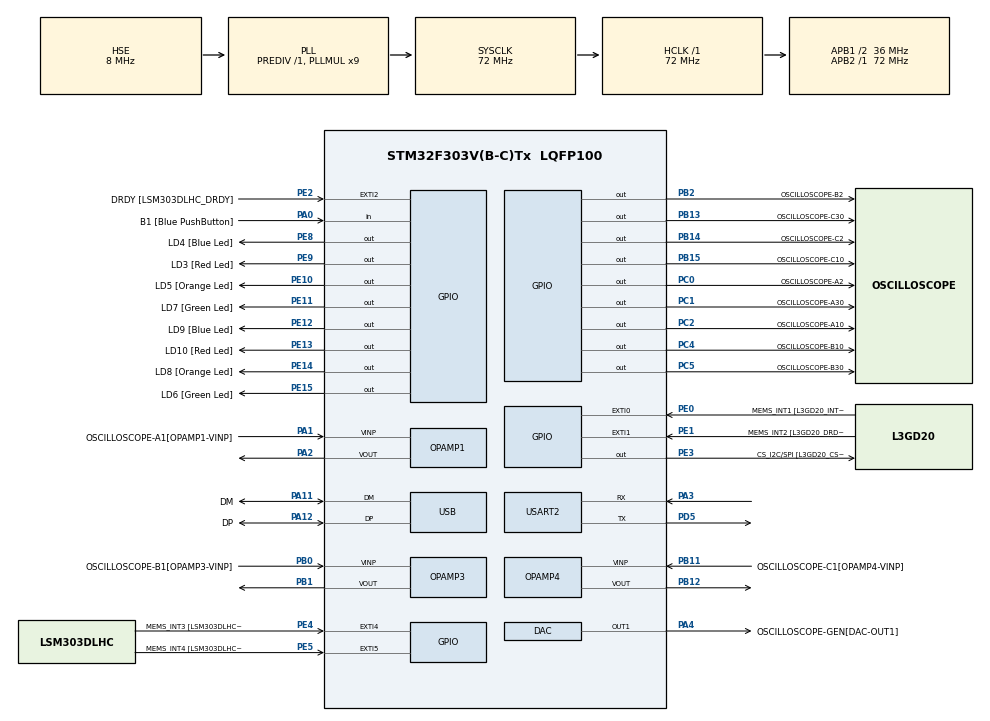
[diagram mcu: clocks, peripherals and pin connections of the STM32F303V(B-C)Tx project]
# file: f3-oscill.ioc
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ADC1.AWD1HighThreshold=4095
ADC1.AWD1ITMode=ENABLE
ADC1.AWD1LowThreshold=0
ADC1.Channel-0\#ChannelRegularConversion=ADC_CHANNEL_3
ADC1.ClockPrescaler=ADC_CLOCK_ASYNC
ADC1.ContinuousConvMode=DISABLE
ADC1.DMAContinuousRequests=ENABLE
ADC1.DataAlign=ADC_DATAALIGN_RIGHT
ADC1.DiscontinuousConvMode=DISABLE
ADC1.EOCSelection=EOC_SINGLE_CONV
ADC1.EnableAnalogWatchDog1=true
ADC1.EnableAnalogWatchDog2=false
ADC1.EnableAnalogWatchDog3=false
ADC1.EnableInjectedConversion=DISABLE
ADC1.EnableRegularConversion=ENABLE
ADC1.ExternalTrigConv=ADC_EXTERNALTRIGCONV_T1_TRGO
ADC1.ExternalTrigConvEdge=ADC_EXTERNALTRIGCONVEDGE_RISING
ADC1.LowPowerAutoWait=DISABLE
ADC1.NbrOfConversion=1
ADC1.NbrOfConversionFlag=1
ADC1.Offset-0\#ChannelRegularConversion=0
ADC1.OffsetNumber-0\#ChannelRegularConversion=ADC_OFFSET_NONE
ADC1.Overrun=OVR_DATA_OVERWRITTEN
ADC1.Rank-0\#ChannelRegularConversion=1
ADC1.Resolution=ADC_RESOLUTION12b
ADC1.SamplingTime-0\#ChannelRegularConversion=ADC_SAMPLETIME_1CYCLE_5
ADC1.ScanConvMode=ADC_SCAN_DISABLE
ADC1.WatchdogChannel=ADC_CHANNEL_3
ADC1.WatchdogMode=ADC_ANALOGWATCHDOG_SINGLE_REG
ADC1.master=1
ADC3.AWD1HighThreshold=4095
ADC3.AWD1ITMode=ENABLE
ADC3.Channel-0\#ChannelRegularConversion=ADC_CHANNEL_1
ADC3.ClockPrescaler=ADC_CLOCK_ASYNC
ADC3.DMAContinuousRequests=ENABLE
ADC3.EnableAnalogWatchDog1=true
ADC3.EnableInjectedConversion=DISABLE
ADC3.ExternalTrigConv=ADC_EXTERNALTRIGCONV_T1_TRGO
ADC3.ExternalTrigConvEdge=ADC_EXTERNALTRIGCONVEDGE_RISING
ADC3.NbrOfConversionFlag=1
ADC3.Offset-0\#ChannelRegularConversion=0
ADC3.OffsetNumber-0\#ChannelRegularConversion=ADC_OFFSET_NONE
ADC3.Rank-0\#ChannelRegularConversion=1
ADC3.SamplingTime-0\#ChannelRegularConversion=ADC_SAMPLETIME_1CYCLE_5
ADC3.master=1
ADC4.AWD1HighThreshold=4095
ADC4.AWD1ITMode=ENABLE
ADC4.Channel-0\#ChannelRegularConversion=ADC_CHANNEL_3
ADC4.DMAContinuousRequests=ENABLE
ADC4.EnableAnalogWatchDog1=true
ADC4.EnableInjectedConversion=DISABLE
ADC4.ExternalTrigConv=ADC_EXTERNALTRIGCONV_T1_TRGO
ADC4.ExternalTrigConvEdge=ADC_EXTERNALTRIGCONVEDGE_RISING
ADC4.NbrOfConversionFlag=1
ADC4.Offset-0\#ChannelRegularConversion=0
ADC4.OffsetNumber-0\#ChannelRegularConversion=ADC_OFFSET_NONE
ADC4.Rank-0\#ChannelRegularConversion=1
ADC4.SamplingTime-0\#ChannelRegularConversion=ADC_SAMPLETIME_1CYCLE_5
ADC4.WatchdogChannel=ADC_CHANNEL_3
DAC.DAC_Trigger=DAC_TRIGGER_T2_TRGO
DAC.WaveGeneration=DISABLE
Dma.ADC1.0.Direction=DMA_PERIPH_TO_MEMORY
Dma.ADC1.0.Instance=DMA1_Channel1
Dma.ADC1.0.MemDataAlignment=DMA_MDATAALIGN_HALFWORD
Dma.ADC1.0.MemInc=DMA_MINC_ENABLE
Dma.ADC1.0.Mode=DMA_CIRCULAR
Dma.ADC1.0.PeriphDataAlignment=DMA_PDATAALIGN_HALFWORD
Dma.ADC1.0.PeriphInc=DMA_PINC_DISABLE
Dma.ADC1.0.Priority=DMA_PRIORITY_LOW
Dma.ADC3.1.Direction=DMA_PERIPH_TO_MEMORY
Dma.ADC3.1.Instance=DMA2_Channel5
Dma.ADC3.1.MemDataAlignment=DMA_MDATAALIGN_HALFWORD
Dma.ADC3.1.MemInc=DMA_MINC_ENABLE
Dma.ADC3.1.Mode=DMA_CIRCULAR
Dma.ADC3.1.PeriphDataAlignment=DMA_PDATAALIGN_HALFWORD
Dma.ADC3.1.PeriphInc=DMA_PINC_DISABLE
Dma.ADC3.1.Priority=DMA_PRIORITY_LOW
Dma.ADC4.2.DMA_Remap=HAL_REMAPDMA_ADC24_DMA2_CH34
Dma.ADC4.2.Direction=DMA_PERIPH_TO_MEMORY
Dma.ADC4.2.Instance=DMA2_Channel4
Dma.ADC4.2.MemDataAlignment=DMA_MDATAALIGN_HALFWORD
Dma.ADC4.2.MemInc=DMA_MINC_ENABLE
Dma.ADC4.2.Mode=DMA_CIRCULAR
Dma.ADC4.2.PeriphDataAlignment=DMA_PDATAALIGN_HALFWORD
Dma.ADC4.2.PeriphInc=DMA_PINC_DISABLE
Dma.ADC4.2.Priority=DMA_PRIORITY_LOW
Dma.DAC_CH1.3.Direction=DMA_MEMORY_TO_PERIPH
Dma.DAC_CH1.3.Instance=DMA2_Channel3
Dma.DAC_CH1.3.MemDataAlignment=DMA_MDATAALIGN_HALFWORD
Dma.DAC_CH1.3.MemInc=DMA_MINC_ENABLE
Dma.DAC_CH1.3.Mode=DMA_CIRCULAR
Dma.DAC_CH1.3.PeriphDataAlignment=DMA_PDATAALIGN_HALFWORD
Dma.DAC_CH1.3.PeriphInc=DMA_PINC_DISABLE
Dma.DAC_CH1.3.Priority=DMA_PRIORITY_LOW
Dma.Request0=ADC1
Dma.Request1=ADC3
Dma.Request2=ADC4
Dma.Request3=DAC_CH1
Mcu.Family=STM32F3
Mcu.Name=STM32F303V(B-C)Tx
Mcu.Package=LQFP100
NVIC.ADC1_2_IRQn=true\:0\:0\:false
NVIC.ADC3_IRQn=true\:0\:0\:false
NVIC.ADC4_IRQn=true\:0\:0\:false
NVIC.DMA1_Channel1_IRQn=true\:0\:0\:false
NVIC.DMA2_Channel3_IRQn=true\:0\:0\:false
NVIC.DMA2_Channel4_IRQn=true\:0\:0\:false
NVIC.DMA2_Channel5_IRQn=true\:0\:0\:false
NVIC.PriorityGroup=NVIC_PRIORITYGROUP_0
NVIC.TIM3_IRQn=true\:0\:0\:false
NVIC.USB_LP_CAN_RX0_IRQn=true\:0\:0\:false
PA0.GPIO_Label=B1 [Blue PushButton]
PA0.GPIO_Mode=GPIO_MODE_INPUT
PA0.GPIO_PuPd=GPIO_NOPULL
PA0.Signal=GPIO_Input
PA1.GPIO_Label=OSCILLOSCOPE-A1[OPAMP1-VINP]
PA1.GPIO_Mode=GPIO_MODE_ANALOG
PA1.GPIO_PuPd=GPIO_NOPULL
PA1.Mode=PGA Not Connected
PA1.Signal=OPAMP1_VINP
PA11.GPIO_Label=DM
PA11.GPIO_Mode=GPIO_MODE_AF_PP
PA11.GPIO_PuPd=GPIO_NOPULL
PA11.GPIO_Speed=GPIO_SPEED_HIGH
PA11.Mode=Device
PA11.Signal=USB_DM
PA12.GPIO_Label=DP
PA12.GPIO_Mode=GPIO_MODE_AF_PP
PA12.GPIO_PuPd=GPIO_NOPULL
PA12.GPIO_Speed=GPIO_SPEED_HIGH
PA12.Mode=Device
PA12.Signal=USB_DP
PA13.GPIO_Label=SWDIO
PA13.Mode=Trace-Asynchronous_SW
PA13.Signal=SYS_JTMS-SWDIO
PA14.GPIO_Label=SWCLK
PA14.Mode=Trace-Asynchronous_SW
PA14.Signal=SYS_JTCK-SWCLK
PA2.Mode=PGA Not Connected
PA2.Signal=OPAMP1_VOUT
PA3.Mode=Asynchronous
PA3.Signal=USART2_RX
PA4.GPIO_Label=OSCILLOSCOPE-GEN[DAC-OUT1]
PA4.GPIO_Mode=GPIO_MODE_ANALOG
PA4.GPIO_PuPd=GPIO_NOPULL
PA4.Signal=COMP_DAC1_group
PA5.GPIO_Label=SPI1_SCK [L3GD20_SCL/SPC]
PA5.GPIO_Mode=GPIO_MODE_AF_PP
PA5.GPIO_PuPd=GPIO_NOPULL
PA5.GPIO_Speed=GPIO_SPEED_LOW
PA5.Signal=SPI1_SCK
PA6.GPIO_Label=SPI1_MISO [L3GD20_SA0/SDO]
PA6.GPIO_Mode=GPIO_MODE_AF_PP
PA6.GPIO_PuPd=GPIO_NOPULL
PA6.GPIO_Speed=GPIO_SPEED_LOW
PA6.Signal=SPI1_MISO
PA7.GPIO_Label=SPI1_MISO [L3GD20_SDA/SDI/SDO]
PA7.GPIO_Mode=GPIO_MODE_AF_PP
PA7.GPIO_PuPd=GPIO_NOPULL
PA7.GPIO_Speed=GPIO_SPEED_LOW
PA7.Signal=SPI1_MOSI
PB0.GPIO_Label=OSCILLOSCOPE-B1[OPAMP3-VINP]
PB0.GPIO_Mode=GPIO_MODE_ANALOG
PB0.GPIO_PuPd=GPIO_NOPULL
PB0.Mode=PGA Not Connected
PB0.Signal=OPAMP3_VINP
PB1.Mode=PGA Not Connected
PB1.Signal=OPAMP3_VOUT
PB11.GPIO_Label=OSCILLOSCOPE-C1[OPAMP4-VINP]
PB11.GPIO_Mode=GPIO_MODE_ANALOG
PB11.GPIO_PuPd=GPIO_NOPULL
PB11.Mode=PGA Not Connected
PB11.Signal=OPAMP4_VINP
PB12.Mode=PGA Not Connected
PB12.Signal=OPAMP4_VOUT
PB13.GPIO_Label=OSCILLOSCOPE-C30
PB13.GPIO_ModeDefaultOutputPP=GPIO_MODE_OUTPUT_OD
PB13.GPIO_PuPd=GPIO_NOPULL
PB13.GPIO_Speed=GPIO_SPEED_HIGH
PB13.Signal=GPIO_Output
PB14.GPIO_Label=OSCILLOSCOPE-C2
PB14.GPIO_ModeDefaultOutputPP=GPIO_MODE_OUTPUT_OD
PB14.GPIO_PuPd=GPIO_NOPULL
PB14.GPIO_Speed=GPIO_SPEED_HIGH
PB14.Signal=GPIO_Output
PB15.GPIO_Label=OSCILLOSCOPE-C10
PB15.GPIO_ModeDefaultOutputPP=GPIO_MODE_OUTPUT_OD
PB15.GPIO_PuPd=GPIO_NOPULL
PB15.GPIO_Speed=GPIO_SPEED_HIGH
PB15.Signal=GPIO_Output
PB2.GPIO_Label=OSCILLOSCOPE-B2
PB2.GPIO_ModeDefaultOutputPP=GPIO_MODE_OUTPUT_OD
PB2.GPIO_PuPd=GPIO_NOPULL
PB2.GPIO_Speed=GPIO_SPEED_HIGH
PB2.Signal=GPIO_Output
PB3.GPIO_Label=SWO
PB3.Mode=Trace-Asynchronous_SW
PB3.Signal=SYS_JTDO-TRACESWO
PB6.GPIO_FM6=__NULL
PB6.GPIO_Label=I2C1_SCL [LSM303DLHC_SCL]
PB6.GPIO_Mode=GPIO_MODE_AF_OD
PB6.GPIO_PuPd=GPIO_NOPULL
PB6.GPIO_PuPdOD=GPIO_PULLUP
PB6.GPIO_Speed=GPIO_SPEED_LOW
PB6.Signal=I2C1_SCL
PB7.GPIO_FM7=__NULL
PB7.GPIO_Label=I2C1_SDA [LSM303DLHC_SDA]
PB7.GPIO_Mode=GPIO_MODE_AF_OD
PB7.GPIO_PuPd=GPIO_NOPULL
PB7.GPIO_PuPdOD=GPIO_PULLUP
PB7.GPIO_Speed=GPIO_SPEED_LOW
PB7.Signal=I2C1_SDA
PC0.GPIO_Label=OSCILLOSCOPE-A2
PC0.GPIO_ModeDefaultOutputPP=GPIO_MODE_OUTPUT_OD
PC0.GPIO_PuPd=GPIO_NOPULL
PC0.GPIO_Speed=GPIO_SPEED_HIGH
PC0.Signal=GPIO_Output
PC1.GPIO_Label=OSCILLOSCOPE-A30
PC1.GPIO_ModeDefaultOutputPP=GPIO_MODE_OUTPUT_OD
PC1.GPIO_PuPd=GPIO_NOPULL
PC1.GPIO_Speed=GPIO_SPEED_HIGH
PC1.Signal=GPIO_Output
PC14-OSC32_IN.GPIO_Label=OSC32_IN
PC14-OSC32_IN.Signal=RCC_OSC32_IN
PC15-OSC32_OUT.GPIO_Label=OSC32_OUT
PC15-OSC32_OUT.Signal=RCC_OSC32_OUT
PC2.GPIO_Label=OSCILLOSCOPE-A10
PC2.GPIO_ModeDefaultOutputPP=GPIO_MODE_OUTPUT_OD
PC2.GPIO_PuPd=GPIO_NOPULL
PC2.GPIO_Speed=GPIO_SPEED_HIGH
PC2.Signal=GPIO_Output
PC4.GPIO_Label=OSCILLOSCOPE-B10
PC4.GPIO_ModeDefaultOutputPP=GPIO_MODE_OUTPUT_OD
PC4.GPIO_PuPd=GPIO_NOPULL
PC4.GPIO_Speed=GPIO_SPEED_HIGH
PC4.Signal=GPIO_Output
PC5.GPIO_Label=OSCILLOSCOPE-B30
PC5.GPIO_ModeDefaultOutputPP=GPIO_MODE_OUTPUT_OD
PC5.GPIO_PuPd=GPIO_NOPULL
PC5.GPIO_Speed=GPIO_SPEED_HIGH
PC5.Signal=GPIO_Output
PD5.Mode=Asynchronous
PD5.Signal=USART2_TX
PE0.GPIO_Label=MEMS_INT1 [L3GD20_INT1]
PE0.GPIO_ModeDefaultEXTI=GPIO_MODE_EVT_RISING
PE0.GPIO_PuPd=GPIO_NOPULL
PE0.Signal=GPXTI0
PE1.GPIO_Label=MEMS_INT2 [L3GD20_DRDY/INT2]
PE1.GPIO_ModeDefaultEXTI=GPIO_MODE_EVT_RISING
PE1.GPIO_PuPd=GPIO_NOPULL
PE1.Signal=GPXTI1
PE10.GPIO_Label=LD5 [Orange Led]
PE10.GPIO_ModeDefaultOutputPP=GPIO_MODE_OUTPUT_PP
PE10.GPIO_PuPd=GPIO_NOPULL
PE10.GPIO_Speed=GPIO_SPEED_LOW
PE10.Signal=GPIO_Output
PE11.GPIO_Label=LD7 [Green Led]
PE11.GPIO_ModeDefaultOutputPP=GPIO_MODE_OUTPUT_PP
PE11.GPIO_PuPd=GPIO_NOPULL
PE11.GPIO_Speed=GPIO_SPEED_LOW
PE11.Signal=GPIO_Output
PE12.GPIO_Label=LD9 [Blue Led]
PE12.GPIO_ModeDefaultOutputPP=GPIO_MODE_OUTPUT_PP
PE12.GPIO_PuPd=GPIO_NOPULL
PE12.GPIO_Speed=GPIO_SPEED_LOW
PE12.Signal=GPIO_Output
PE13.GPIO_Label=LD10 [Red Led]
PE13.GPIO_ModeDefaultOutputPP=GPIO_MODE_OUTPUT_PP
PE13.GPIO_PuPd=GPIO_NOPULL
PE13.GPIO_Speed=GPIO_SPEED_LOW
PE13.Signal=GPIO_Output
PE14.GPIO_Label=LD8 [Orange Led]
PE14.GPIO_ModeDefaultOutputPP=GPIO_MODE_OUTPUT_PP
PE14.GPIO_PuPd=GPIO_NOPULL
PE14.GPIO_Speed=GPIO_SPEED_LOW
PE14.Signal=GPIO_Output
PE15.GPIO_Label=LD6 [Green Led]
PE15.GPIO_ModeDefaultOutputPP=GPIO_MODE_OUTPUT_PP
PE15.GPIO_PuPd=GPIO_NOPULL
PE15.GPIO_Speed=GPIO_SPEED_LOW
PE15.Signal=GPIO_Output
PE2.GPIO_Label=DRDY [LSM303DLHC_DRDY]
PE2.GPIO_ModeDefaultEXTI=GPIO_MODE_EVT_RISING
PE2.GPIO_PuPd=GPIO_NOPULL
PE2.Signal=GPXTI2
PE3.GPIO_Label=CS_I2C/SPI [L3GD20_CS_I2C/SPI]
PE3.GPIO_ModeDefaultOutputPP=GPIO_MODE_OUTPUT_PP
PE3.GPIO_PuPd=GPIO_NOPULL
PE3.GPIO_Speed=GPIO_SPEED_LOW
PE3.Signal=GPIO_Output
PE4.GPIO_Label=MEMS_INT3 [LSM303DLHC_INT1]
PE4.GPIO_ModeDefaultEXTI=GPIO_MODE_EVT_RISING
PE4.GPIO_PuPd=GPIO_NOPULL
PE4.Signal=GPXTI4
PE5.GPIO_Label=MEMS_INT4 [LSM303DLHC_INT2]
PE5.GPIO_ModeDefaultEXTI=GPIO_MODE_EVT_RISING
PE5.GPIO_PuPd=GPIO_NOPULL
PE5.Signal=GPXTI5
PE7.GPIO_Label=OSCILLOSCOPE-EXT_SYNC[COMP4_INP]
PE7.GPIO_Mode=GPIO_MODE_ANALOG
PE7.GPIO_PuPd=GPIO_NOPULL
PE7.Signal=COMP4_INP
PE8.GPIO_Label=LD4 [Blue Led]
PE8.GPIO_ModeDefaultOutputPP=GPIO_MODE_OUTPUT_PP
PE8.GPIO_PuPd=GPIO_NOPULL
PE8.GPIO_Speed=GPIO_SPEED_LOW
PE8.Signal=GPIO_Output
PE9.GPIO_Label=LD3 [Red Led]
PE9.GPIO_ModeDefaultOutputPP=GPIO_MODE_OUTPUT_PP
PE9.GPIO_PuPd=GPIO_NOPULL
PE9.GPIO_Speed=GPIO_SPEED_LOW
PE9.Signal=GPIO_Output
PF0-OSC_IN.GPIO_Label=OSC_IN
PF0-OSC_IN.Mode=HSE-External-Clock-Source
PF0-OSC_IN.Signal=RCC_OSC_IN
PF1-OSC_OUT.GPIO_Label=OSC_OUT
PF1-OSC_OUT.Signal=RCC_OSC_OUT
ProjectManager.TargetToolchain=MDK-ARM V5
RCC.AHBFreq_Value=72000000
RCC.APB1CLKDivider=RCC_HCLK_DIV2
RCC.APB1Freq_Value=36000000
RCC.APB1TimFreq_Value=72000000
RCC.APB2Freq_Value=72000000
RCC.APB2TimFreq_Value=72000000
RCC.CortexFreq_Value=9000000
RCC.Cortex_Div=SYSTICK_CLKSOURCE_HCLK_DIV8
RCC.HCLKFreq_Value=72000000
RCC.HSE_VALUE=8000000
RCC.HSIState=RCC_HSI_ON
RCC.HSI_VALUE=8000000
RCC.LSE_VALUE=32768
RCC.PLLMUL=RCC_PLL_MUL9
RCC.PRESCALERUSB=RCC_USBPLLCLK_DIV1_5
RCC.SYSCLKFreq_VALUE=72000000
RCC.SYSCLKSourceVirtual=RCC_SYSCLKSOURCE_PLLCLK
RCC.USBFreq_Value=48000000
SH.COMP_DAC1_group.0=DAC_OUT1,DAC_OUT1
TIM1.Period=3000
TIM1.TIM_MasterOutputTrigger=TIM_TRGO_UPDATE
TIM2.Period=2000
TIM2.TIM_MasterOutputTrigger=TIM_TRGO_UPDATE
TIM3.Period=2095
VP_ADC1_OPAMP_OUT1.Mode=IN-OPAMP1-Single-Ended
VP_ADC3_OPAMP_OUT3.Mode=IN-OPAMP3-Single-Ended
VP_ADC4_OPAMP_OUT4.Mode=IN-OPAMP4-Single-Ended
VP_TIM1_VS_ClockSourceINT.Mode=Internal
VP_TIM2_VS_ClockSourceINT.Mode=Internal
VP_TIM3_VS_ClockSourceITR.Mode=TriggerSource_ITR0
VP_TIM3_VS_ControllerModeClock.Mode=Clock Mode
board=STM32F3DISCOVERY

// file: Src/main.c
/**
  ******************************************************************************
  * File Name          : main.c
  * Description        : Main program body
  ******************************************************************************
  *
  * COPYRIGHT(c) 2016 STMicroelectronics
  *
  * Redistribution and use in source and binary forms, with or without modification,
  * are permitted provided that the following conditions are met:
  *   1. Redistributions of source code must retain the above copyright notice,
  *      this list of conditions and the following disclaimer.
  *   2. Redistributions in binary form must reproduce the above copyright notice,
  *      this list of conditions and the following disclaimer in the documentation
  *      and/or other materials provided with the distribution.
  *   3. Neither the name of STMicroelectronics nor the names of its contributors
  *      may be used to endorse or promote products derived from this software
  *      without specific prior written permission.
  *
  * THIS SOFTWARE IS PROVIDED BY THE COPYRIGHT HOLDERS AND CONTRIBUTORS "AS IS"
  * AND ANY EXPRESS OR IMPLIED WARRANTIES, INCLUDING, BUT NOT LIMITED TO, THE
  * IMPLIED WARRANTIES OF MERCHANTABILITY AND FITNESS FOR A PARTICULAR PURPOSE ARE
  * DISCLAIMED. IN NO EVENT SHALL THE COPYRIGHT HOLDER OR CONTRIBUTORS BE LIABLE
  * FOR ANY DIRECT, INDIRECT, INCIDENTAL, SPECIAL, EXEMPLARY, OR CONSEQUENTIAL
  * DAMAGES (INCLUDING, BUT NOT LIMITED TO, PROCUREMENT OF SUBSTITUTE GOODS OR
  * SERVICES; LOSS OF USE, DATA, OR PROFITS; OR BUSINESS INTERRUPTION) HOWEVER
  * CAUSED AND ON ANY THEORY OF LIABILITY, WHETHER IN CONTRACT, STRICT LIABILITY,
  * OR TORT (INCLUDING NEGLIGENCE OR OTHERWISE) ARISING IN ANY WAY OUT OF THE USE
  * OF THIS SOFTWARE, EVEN IF ADVISED OF THE POSSIBILITY OF SUCH DAMAGE.
  *
  ******************************************************************************
  */
#include "stm32f3xx_hal.h"

/* USER CODE BEGIN Includes */
#include "usb_device.h"
#include "usbd_oscill_if.h"
#include "oscill.h"

/* USER CODE END Includes */

ADC_HandleTypeDef hadc1;
ADC_HandleTypeDef hadc3;
ADC_HandleTypeDef hadc4;
DMA_HandleTypeDef hdma_adc1;
DMA_HandleTypeDef hdma_adc3;
DMA_HandleTypeDef hdma_adc4;

DAC_HandleTypeDef hdac;
DMA_HandleTypeDef hdma_dac_ch1;

OPAMP_HandleTypeDef hopamp1;
OPAMP_HandleTypeDef hopamp3;
OPAMP_HandleTypeDef hopamp4;

TIM_HandleTypeDef htim1;
TIM_HandleTypeDef htim2;
TIM_HandleTypeDef htim3;

UART_HandleTypeDef huart2;

PCD_HandleTypeDef hpcd_USB_FS;

/* USER CODE BEGIN PV */
/* Private variables ---------------------------------------------------------*/
/* USER CODE END PV */

void SystemClock_Config(void);
static void MX_GPIO_Init(void);
static void MX_DMA_Init(void);
static void MX_ADC1_Init(void);
static void MX_ADC3_Init(void);
static void MX_ADC4_Init(void);
static void MX_DAC_Init(void);
static void MX_OPAMP1_Init(void);
static void MX_OPAMP3_Init(void);
static void MX_OPAMP4_Init(void);
static void MX_TIM1_Init(void);
static void MX_TIM2_Init(void);
static void MX_TIM3_Init(void);
static void MX_USART2_UART_Init(void);
static void MX_USB_PCD_Init(void);

/* USER CODE BEGIN PFP */
/* Private function prototypes -----------------------------------------------*/

/* USER CODE END PFP */

int main(void)
{

  /* USER CODE BEGIN 1 */
 	MX_USB_DEVICE_Init();

  /* USER CODE END 1 */

  /* MCU Configuration----------------------------------------------------------*/

  /* Reset of all peripherals, Initializes the Flash interface and the Systick. */
  HAL_Init();

  /* Configure the system clock */
  SystemClock_Config();

  /* Initialize all configured peripherals */
  MX_GPIO_Init();
  MX_DMA_Init();
  MX_ADC1_Init();
  MX_ADC3_Init();
  MX_ADC4_Init();
  MX_DAC_Init();
  MX_OPAMP1_Init();
  MX_OPAMP3_Init();
  MX_OPAMP4_Init();
  MX_TIM1_Init();
  MX_TIM2_Init();
  MX_TIM3_Init();
  MX_USART2_UART_Init();
  MX_USB_PCD_Init();

  /* USER CODE BEGIN 2 */
	initOscill();
  /* USER CODE END 2 */

  /* Infinite loop */
  while (1)
  {

  }

}

/** System Clock Configuration
*/
void SystemClock_Config(void)
{

  RCC_OscInitTypeDef RCC_OscInitStruct;
  RCC_ClkInitTypeDef RCC_ClkInitStruct;
  RCC_PeriphCLKInitTypeDef PeriphClkInit;

  RCC_OscInitStruct.OscillatorType = RCC_OSCILLATORTYPE_HSE;
  RCC_OscInitStruct.HSEState = RCC_HSE_BYPASS;
  RCC_OscInitStruct.HSEPredivValue = RCC_HSE_PREDIV_DIV1;
  RCC_OscInitStruct.PLL.PLLState = RCC_PLL_ON;
  RCC_OscInitStruct.PLL.PLLSource = RCC_PLLSOURCE_HSE;
  RCC_OscInitStruct.PLL.PLLMUL = RCC_PLL_MUL9;
  HAL_RCC_OscConfig(&RCC_OscInitStruct);

  RCC_ClkInitStruct.ClockType = RCC_CLOCKTYPE_SYSCLK|RCC_CLOCKTYPE_PCLK1;
  RCC_ClkInitStruct.SYSCLKSource = RCC_SYSCLKSOURCE_PLLCLK;
  RCC_ClkInitStruct.AHBCLKDivider = RCC_SYSCLK_DIV1;
  RCC_ClkInitStruct.APB1CLKDivider = RCC_HCLK_DIV2;
  RCC_ClkInitStruct.APB2CLKDivider = RCC_HCLK_DIV1;
  HAL_RCC_ClockConfig(&RCC_ClkInitStruct, FLASH_LATENCY_2);

  PeriphClkInit.PeriphClockSelection = RCC_PERIPHCLK_USB|RCC_PERIPHCLK_USART2
                              |RCC_PERIPHCLK_TIM1|RCC_PERIPHCLK_ADC12
                              |RCC_PERIPHCLK_ADC34;
  PeriphClkInit.Usart2ClockSelection = RCC_USART2CLKSOURCE_PCLK1;
  PeriphClkInit.Adc12ClockSelection = RCC_ADC12PLLCLK_DIV1;
  PeriphClkInit.Adc34ClockSelection = RCC_ADC34PLLCLK_DIV1;
  PeriphClkInit.USBClockSelection = RCC_USBPLLCLK_DIV1_5;
  PeriphClkInit.Tim1ClockSelection = RCC_TIM1CLK_HCLK;
  HAL_RCCEx_PeriphCLKConfig(&PeriphClkInit);

  HAL_SYSTICK_Config(HAL_RCC_GetHCLKFreq()/8000);

  HAL_SYSTICK_CLKSourceConfig(SYSTICK_CLKSOURCE_HCLK_DIV8);

  /* SysTick_IRQn interrupt configuration */
  HAL_NVIC_SetPriority(SysTick_IRQn, 0, 0);
}

/* ADC1 init function */
void MX_ADC1_Init(void)
{

  ADC_AnalogWDGConfTypeDef AnalogWDGConfig;
  ADC_ChannelConfTypeDef sConfig;

    /**Common config
    */
  hadc1.Instance = ADC1;
  hadc1.Init.ClockPrescaler = ADC_CLOCK_ASYNC;
  hadc1.Init.Resolution = ADC_RESOLUTION12b;
  hadc1.Init.ScanConvMode = ADC_SCAN_DISABLE;
  hadc1.Init.ContinuousConvMode = DISABLE;
  hadc1.Init.DiscontinuousConvMode = DISABLE;
  hadc1.Init.ExternalTrigConvEdge = ADC_EXTERNALTRIGCONVEDGE_RISING;
  hadc1.Init.ExternalTrigConv = ADC_EXTERNALTRIGCONV_T1_TRGO;
  hadc1.Init.DataAlign = ADC_DATAALIGN_RIGHT;
  hadc1.Init.NbrOfConversion = 1;
  hadc1.Init.DMAContinuousRequests = ENABLE;
  hadc1.Init.EOCSelection = EOC_SINGLE_CONV;
  hadc1.Init.LowPowerAutoWait = DISABLE;
  hadc1.Init.Overrun = OVR_DATA_OVERWRITTEN;
  HAL_ADC_Init(&hadc1);

    /**Configure Analog WatchDog 1
    */
  AnalogWDGConfig.WatchdogNumber = ADC_ANALOGWATCHDOG_1;
  AnalogWDGConfig.WatchdogMode = ADC_ANALOGWATCHDOG_SINGLE_REG;
  AnalogWDGConfig.HighThreshold = 4095;
  AnalogWDGConfig.LowThreshold = 0;
  AnalogWDGConfig.Channel = ADC_CHANNEL_3;
  AnalogWDGConfig.ITMode = ENABLE;
  HAL_ADC_AnalogWDGConfig(&hadc1, &AnalogWDGConfig);

    /**Configure Regular Channel
    */
  sConfig.Channel = ADC_CHANNEL_3;
  sConfig.Rank = 1;
  sConfig.SingleDiff = ADC_SINGLE_ENDED;
  sConfig.SamplingTime = ADC_SAMPLETIME_1CYCLE_5;
  sConfig.OffsetNumber = ADC_OFFSET_NONE;
  sConfig.Offset = 0;
  HAL_ADC_ConfigChannel(&hadc1, &sConfig);

}

/* ADC3 init function */
void MX_ADC3_Init(void)
{

  ADC_AnalogWDGConfTypeDef AnalogWDGConfig;
  ADC_ChannelConfTypeDef sConfig;

    /**Common config
    */
  hadc3.Instance = ADC3;
  hadc3.Init.ClockPrescaler = ADC_CLOCK_ASYNC;
  hadc3.Init.Resolution = ADC_RESOLUTION12b;
  hadc3.Init.ScanConvMode = ADC_SCAN_DISABLE;
  hadc3.Init.ContinuousConvMode = DISABLE;
  hadc3.Init.DiscontinuousConvMode = DISABLE;
  hadc3.Init.ExternalTrigConvEdge = ADC_EXTERNALTRIGCONVEDGE_RISING;
  hadc3.Init.ExternalTrigConv = ADC_EXTERNALTRIGCONV_T1_TRGO;
  hadc3.Init.DataAlign = ADC_DATAALIGN_RIGHT;
  hadc3.Init.NbrOfConversion = 1;
  hadc3.Init.DMAContinuousRequests = ENABLE;
  hadc3.Init.EOCSelection = EOC_SINGLE_CONV;
  hadc3.Init.LowPowerAutoWait = DISABLE;
  hadc3.Init.Overrun = OVR_DATA_OVERWRITTEN;
  HAL_ADC_Init(&hadc3);

    /**Configure Analog WatchDog 1
    */
  AnalogWDGConfig.WatchdogNumber = ADC_ANALOGWATCHDOG_1;
  AnalogWDGConfig.WatchdogMode = ADC_ANALOGWATCHDOG_SINGLE_REG;
  AnalogWDGConfig.HighThreshold = 4095;
  AnalogWDGConfig.LowThreshold = 0;
  AnalogWDGConfig.Channel = ADC_CHANNEL_1;
  AnalogWDGConfig.ITMode = ENABLE;
  HAL_ADC_AnalogWDGConfig(&hadc3, &AnalogWDGConfig);

    /**Configure Regular Channel
    */
  sConfig.Channel = ADC_CHANNEL_1;
  sConfig.Rank = 1;
  sConfig.SingleDiff = ADC_SINGLE_ENDED;
  sConfig.SamplingTime = ADC_SAMPLETIME_1CYCLE_5;
  sConfig.OffsetNumber = ADC_OFFSET_NONE;
  sConfig.Offset = 0;
  HAL_ADC_ConfigChannel(&hadc3, &sConfig);

}

/* ADC4 init function */
void MX_ADC4_Init(void)
{

  ADC_AnalogWDGConfTypeDef AnalogWDGConfig;
  ADC_ChannelConfTypeDef sConfig;

    /**Common config
    */
  hadc4.Instance = ADC4;
  hadc4.Init.ClockPrescaler = ADC_CLOCK_ASYNC;
  hadc4.Init.Resolution = ADC_RESOLUTION12b;
  hadc4.Init.ScanConvMode = ADC_SCAN_DISABLE;
  hadc4.Init.ContinuousConvMode = DISABLE;
  hadc4.Init.DiscontinuousConvMode = DISABLE;
  hadc4.Init.ExternalTrigConvEdge = ADC_EXTERNALTRIGCONVEDGE_RISING;
  hadc4.Init.ExternalTrigConv = ADC_EXTERNALTRIGCONV_T1_TRGO;
  hadc4.Init.DataAlign = ADC_DATAALIGN_RIGHT;
  hadc4.Init.NbrOfConversion = 1;
  hadc4.Init.DMAContinuousRequests = ENABLE;
  hadc4.Init.EOCSelection = EOC_SINGLE_CONV;
  hadc4.Init.LowPowerAutoWait = DISABLE;
  hadc4.Init.Overrun = OVR_DATA_OVERWRITTEN;
  HAL_ADC_Init(&hadc4);

    /**Configure Analog WatchDog 1
    */
  AnalogWDGConfig.WatchdogNumber = ADC_ANALOGWATCHDOG_1;
  AnalogWDGConfig.WatchdogMode = ADC_ANALOGWATCHDOG_SINGLE_REG;
  AnalogWDGConfig.HighThreshold = 4095;
  AnalogWDGConfig.LowThreshold = 0;
  AnalogWDGConfig.Channel = ADC_CHANNEL_3;
  AnalogWDGConfig.ITMode = ENABLE;
  HAL_ADC_AnalogWDGConfig(&hadc4, &AnalogWDGConfig);

    /**Configure Regular Channel
    */
  sConfig.Channel = ADC_CHANNEL_3;
  sConfig.Rank = 1;
  sConfig.SingleDiff = ADC_SINGLE_ENDED;
  sConfig.SamplingTime = ADC_SAMPLETIME_1CYCLE_5;
  sConfig.OffsetNumber = ADC_OFFSET_NONE;
  sConfig.Offset = 0;
  HAL_ADC_ConfigChannel(&hadc4, &sConfig);

}

/* DAC init function */
void MX_DAC_Init(void)
{

  DAC_ChannelConfTypeDef sConfig;

    /**DAC Initialization
    */
  hdac.Instance = DAC;
  HAL_DAC_Init(&hdac);

    /**DAC channel OUT1 config
    */
  sConfig.DAC_Trigger = DAC_TRIGGER_T2_TRGO;
  sConfig.DAC_OutputBuffer = DAC_OUTPUTBUFFER_ENABLE;
  HAL_DAC_ConfigChannel(&hdac, &sConfig, DAC_CHANNEL_1);

}

/* OPAMP1 init function */
void MX_OPAMP1_Init(void)
{

  hopamp1.Instance = OPAMP1;
  hopamp1.Init.Mode = OPAMP_PGA_MODE;
  hopamp1.Init.NonInvertingInput = OPAMP_NONINVERTINGINPUT_VP0;
  hopamp1.Init.TimerControlledMuxmode = OPAMP_TIMERCONTROLLEDMUXMODE_DISABLE;
  hopamp1.Init.PgaConnect = OPAMP_PGACONNECT_NO;
  hopamp1.Init.PgaGain = OPAMP_PGA_GAIN_2;
  hopamp1.Init.UserTrimming = OPAMP_TRIMMING_FACTORY;
  HAL_OPAMP_Init(&hopamp1);

}

/* OPAMP3 init function */
void MX_OPAMP3_Init(void)
{

  hopamp3.Instance = OPAMP3;
  hopamp3.Init.Mode = OPAMP_PGA_MODE;
  hopamp3.Init.NonInvertingInput = OPAMP_NONINVERTINGINPUT_VP0;
  hopamp3.Init.TimerControlledMuxmode = OPAMP_TIMERCONTROLLEDMUXMODE_DISABLE;
  hopamp3.Init.PgaConnect = OPAMP_PGACONNECT_NO;
  hopamp3.Init.PgaGain = OPAMP_PGA_GAIN_2;
  hopamp3.Init.UserTrimming = OPAMP_TRIMMING_FACTORY;
  HAL_OPAMP_Init(&hopamp3);

}

/* OPAMP4 init function */
void MX_OPAMP4_Init(void)
{

  hopamp4.Instance = OPAMP4;
  hopamp4.Init.Mode = OPAMP_PGA_MODE;
  hopamp4.Init.NonInvertingInput = OPAMP_NONINVERTINGINPUT_VP2;
  hopamp4.Init.TimerControlledMuxmode = OPAMP_TIMERCONTROLLEDMUXMODE_DISABLE;
  hopamp4.Init.PgaConnect = OPAMP_PGACONNECT_NO;
  hopamp4.Init.PgaGain = OPAMP_PGA_GAIN_2;
  hopamp4.Init.UserTrimming = OPAMP_TRIMMING_FACTORY;
  HAL_OPAMP_Init(&hopamp4);

}

/* TIM1 init function */
void MX_TIM1_Init(void)
{

  TIM_ClockConfigTypeDef sClockSourceConfig;
  TIM_MasterConfigTypeDef sMasterConfig;

  htim1.Instance = TIM1;
  htim1.Init.Prescaler = 0;
  htim1.Init.CounterMode = TIM_COUNTERMODE_UP;
  htim1.Init.Period = 3000;
  htim1.Init.ClockDivision = TIM_CLOCKDIVISION_DIV1;
  htim1.Init.RepetitionCounter = 0;
  HAL_TIM_Base_Init(&htim1);

  sClockSourceConfig.ClockSource = TIM_CLOCKSOURCE_INTERNAL;
  HAL_TIM_ConfigClockSource(&htim1, &sClockSourceConfig);

  sMasterConfig.MasterOutputTrigger = TIM_TRGO_UPDATE;
  sMasterConfig.MasterOutputTrigger2 = TIM_TRGO2_RESET;
  sMasterConfig.MasterSlaveMode = TIM_MASTERSLAVEMODE_DISABLE;
  HAL_TIMEx_MasterConfigSynchronization(&htim1, &sMasterConfig);

}

/* TIM2 init function */
void MX_TIM2_Init(void)
{

  TIM_ClockConfigTypeDef sClockSourceConfig;
  TIM_MasterConfigTypeDef sMasterConfig;

  htim2.Instance = TIM2;
  htim2.Init.Prescaler = 0;
  htim2.Init.CounterMode = TIM_COUNTERMODE_UP;
  htim2.Init.Period = 2000;
  htim2.Init.ClockDivision = TIM_CLOCKDIVISION_DIV1;
  HAL_TIM_Base_Init(&htim2);

  sClockSourceConfig.ClockSource = TIM_CLOCKSOURCE_INTERNAL;
  HAL_TIM_ConfigClockSource(&htim2, &sClockSourceConfig);

  sMasterConfig.MasterOutputTrigger = TIM_TRGO_UPDATE;
  sMasterConfig.MasterSlaveMode = TIM_MASTERSLAVEMODE_DISABLE;
  HAL_TIMEx_MasterConfigSynchronization(&htim2, &sMasterConfig);

}

/* TIM3 init function */
void MX_TIM3_Init(void)
{

  TIM_SlaveConfigTypeDef sSlaveConfig;
  TIM_MasterConfigTypeDef sMasterConfig;

  htim3.Instance = TIM3;
  htim3.Init.Prescaler = 0;
  htim3.Init.CounterMode = TIM_COUNTERMODE_UP;
  htim3.Init.Period = 2095;
  htim3.Init.ClockDivision = TIM_CLOCKDIVISION_DIV1;
  HAL_TIM_Base_Init(&htim3);

  sSlaveConfig.SlaveMode = TIM_SLAVEMODE_EXTERNAL1;
  sSlaveConfig.InputTrigger = TIM_TS_ITR0;
  HAL_TIM_SlaveConfigSynchronization(&htim3, &sSlaveConfig);

  sMasterConfig.MasterOutputTrigger = TIM_TRGO_RESET;
  sMasterConfig.MasterSlaveMode = TIM_MASTERSLAVEMODE_DISABLE;
  HAL_TIMEx_MasterConfigSynchronization(&htim3, &sMasterConfig);

}

/* USART2 init function */
void MX_USART2_UART_Init(void)
{

  huart2.Instance = USART2;
  huart2.Init.BaudRate = 38400;
  huart2.Init.WordLength = UART_WORDLENGTH_8B;
  huart2.Init.StopBits = UART_STOPBITS_1;
  huart2.Init.Parity = UART_PARITY_NONE;
  huart2.Init.Mode = UART_MODE_TX_RX;
  huart2.Init.HwFlowCtl = UART_HWCONTROL_NONE;
  huart2.Init.OverSampling = UART_OVERSAMPLING_16;
  huart2.Init.OneBitSampling = UART_ONEBIT_SAMPLING_DISABLED ;
  huart2.AdvancedInit.AdvFeatureInit = UART_ADVFEATURE_NO_INIT;
  HAL_UART_Init(&huart2);

}

/* USB init function */
void MX_USB_PCD_Init(void)
{

  hpcd_USB_FS.Instance = USB;
  hpcd_USB_FS.Init.dev_endpoints = 8;
  hpcd_USB_FS.Init.speed = PCD_SPEED_FULL;
  hpcd_USB_FS.Init.ep0_mps = DEP0CTL_MPS_64;
  hpcd_USB_FS.Init.phy_itface = PCD_PHY_EMBEDDED;
  hpcd_USB_FS.Init.low_power_enable = DISABLE;
  hpcd_USB_FS.Init.battery_charging_enable = DISABLE;
  HAL_PCD_Init(&hpcd_USB_FS);

}

void MX_DMA_Init(void)
{
  /* DMA controller clock enable */
  __DMA1_CLK_ENABLE();
  __DMA2_CLK_ENABLE();

  /* DMA interrupt init */
  HAL_NVIC_SetPriority(DMA1_Channel1_IRQn, 0, 0);
  HAL_NVIC_EnableIRQ(DMA1_Channel1_IRQn);
  HAL_NVIC_SetPriority(DMA2_Channel3_IRQn, 0, 0);
  HAL_NVIC_EnableIRQ(DMA2_Channel3_IRQn);
  HAL_NVIC_SetPriority(DMA2_Channel4_IRQn, 0, 0);
  HAL_NVIC_EnableIRQ(DMA2_Channel4_IRQn);
  HAL_NVIC_SetPriority(DMA2_Channel5_IRQn, 0, 0);
  HAL_NVIC_EnableIRQ(DMA2_Channel5_IRQn);

}

/** Configure pins as
        * Analog
        * Input
        * Output
        * EVENT_OUT
        * EXTI
     PA5   ------> SPI1_SCK
     PA6   ------> SPI1_MISO
     PA7   ------> SPI1_MOSI
     PE7   ------> COMP4_INP
     PB6   ------> I2C1_SCL
     PB7   ------> I2C1_SDA
*/
void MX_GPIO_Init(void)
{

  GPIO_InitTypeDef GPIO_InitStruct;

  /* GPIO Ports Clock Enable */
  __GPIOE_CLK_ENABLE();
  __GPIOC_CLK_ENABLE();
  __GPIOF_CLK_ENABLE();
  __GPIOA_CLK_ENABLE();
  __GPIOB_CLK_ENABLE();
  __GPIOD_CLK_ENABLE();

  /*Configure GPIO pins : DRDY_Pin MEMS_INT3_Pin MEMS_INT4_Pin MEMS_INT1_Pin
                           MEMS_INT2_Pin */
  GPIO_InitStruct.Pin = DRDY_Pin|MEMS_INT3_Pin|MEMS_INT4_Pin|MEMS_INT1_Pin
                          |MEMS_INT2_Pin;
  GPIO_InitStruct.Mode = GPIO_MODE_EVT_RISING;
  GPIO_InitStruct.Pull = GPIO_NOPULL;
  HAL_GPIO_Init(GPIOE, &GPIO_InitStruct);

  /*Configure GPIO pins : CS_I2C_SPI_Pin LD4_Pin LD3_Pin LD5_Pin
                           LD7_Pin LD9_Pin LD10_Pin LD8_Pin
                           LD6_Pin */
  GPIO_InitStruct.Pin = CS_I2C_SPI_Pin|LD4_Pin|LD3_Pin|LD5_Pin
                          |LD7_Pin|LD9_Pin|LD10_Pin|LD8_Pin
                          |LD6_Pin;
  GPIO_InitStruct.Mode = GPIO_MODE_OUTPUT_PP;
  GPIO_InitStruct.Pull = GPIO_NOPULL;
  GPIO_InitStruct.Speed = GPIO_SPEED_LOW;
  HAL_GPIO_Init(GPIOE, &GPIO_InitStruct);

  /*Configure GPIO pins : OSCILLOSCOPE_A2_Pin OSCILLOSCOPE_A30_Pin OSCILLOSCOPE_A10_Pin OSCILLOSCOPE_B10_Pin
                           OSCILLOSCOPE_B30_Pin */
  GPIO_InitStruct.Pin = OSCILLOSCOPE_A2_Pin|OSCILLOSCOPE_A30_Pin|OSCILLOSCOPE_A10_Pin|OSCILLOSCOPE_B10_Pin
                          |OSCILLOSCOPE_B30_Pin;
  GPIO_InitStruct.Mode = GPIO_MODE_OUTPUT_OD;
  GPIO_InitStruct.Pull = GPIO_NOPULL;
  GPIO_InitStruct.Speed = GPIO_SPEED_HIGH;
  HAL_GPIO_Init(GPIOC, &GPIO_InitStruct);

  /*Configure GPIO pin : B1_Pin */
  GPIO_InitStruct.Pin = B1_Pin;
  GPIO_InitStruct.Mode = GPIO_MODE_INPUT;
  GPIO_InitStruct.Pull = GPIO_NOPULL;
  HAL_GPIO_Init(B1_GPIO_Port, &GPIO_InitStruct);

  /*Configure GPIO pins : PA5 PA6 SPI1_MISO_Pin */
  GPIO_InitStruct.Pin = GPIO_PIN_5|GPIO_PIN_6|SPI1_MISO_Pin;
  GPIO_InitStruct.Mode = GPIO_MODE_AF_PP;
  GPIO_InitStruct.Pull = GPIO_NOPULL;
  GPIO_InitStruct.Speed = GPIO_SPEED_LOW;
  GPIO_InitStruct.Alternate = GPIO_AF5_SPI1;
  HAL_GPIO_Init(GPIOA, &GPIO_InitStruct);

  /*Configure GPIO pins : OSCILLOSCOPE_B2_Pin OSCILLOSCOPE_C30_Pin OSCILLOSCOPE_C2_Pin OSCILLOSCOPE_C10_Pin */
  GPIO_InitStruct.Pin = OSCILLOSCOPE_B2_Pin|OSCILLOSCOPE_C30_Pin|OSCILLOSCOPE_C2_Pin|OSCILLOSCOPE_C10_Pin;
  GPIO_InitStruct.Mode = GPIO_MODE_OUTPUT_OD;
  GPIO_InitStruct.Pull = GPIO_NOPULL;
  GPIO_InitStruct.Speed = GPIO_SPEED_HIGH;
  HAL_GPIO_Init(GPIOB, &GPIO_InitStruct);

  /*Configure GPIO pin : OSCILLOSCOPE_EXT_SYNC_Pin */
  GPIO_InitStruct.Pin = OSCILLOSCOPE_EXT_SYNC_Pin;
  GPIO_InitStruct.Mode = GPIO_MODE_ANALOG;
  GPIO_InitStruct.Pull = GPIO_NOPULL;
  HAL_GPIO_Init(OSCILLOSCOPE_EXT_SYNC_GPIO_Port, &GPIO_InitStruct);

  /*Configure GPIO pins : PB6 PB7 */
  GPIO_InitStruct.Pin = GPIO_PIN_6|GPIO_PIN_7;
  GPIO_InitStruct.Mode = GPIO_MODE_AF_OD;
  GPIO_InitStruct.Pull = GPIO_PULLUP;
  GPIO_InitStruct.Speed = GPIO_SPEED_LOW;
  GPIO_InitStruct.Alternate = GPIO_AF4_I2C1;
  HAL_GPIO_Init(GPIOB, &GPIO_InitStruct);

}

/************************ (C) COPYRIGHT STMicroelectronics *****END OF FILE****/
